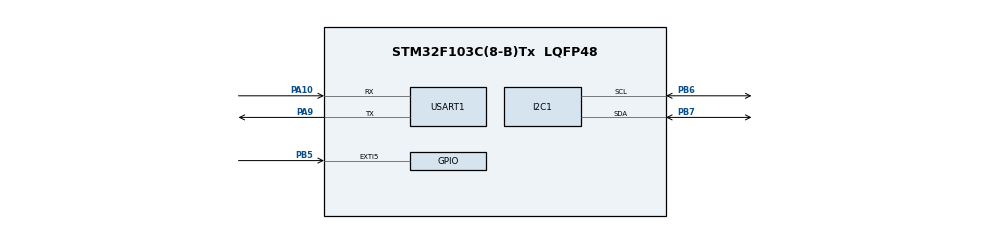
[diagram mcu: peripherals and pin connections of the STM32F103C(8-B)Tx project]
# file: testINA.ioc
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Mcu.Family=STM32F1
Mcu.Name=STM32F103C(8-B)Tx
Mcu.Package=LQFP48
NVIC.EXTI9_5_IRQn=true\:0\:0\:false\:false\:true\:true\:true
NVIC.I2C1_EV_IRQn=true\:0\:0\:false\:false\:true\:true\:true
NVIC.PriorityGroup=NVIC_PRIORITYGROUP_4
NVIC.USART1_IRQn=true\:0\:0\:false\:false\:true\:true\:true
PA10.Mode=Asynchronous
PA10.Signal=USART1_RX
PA13.Mode=Serial_Wire
PA13.Signal=SYS_JTMS-SWDIO
PA14.Mode=Serial_Wire
PA14.Signal=SYS_JTCK-SWCLK
PA9.Mode=Asynchronous
PA9.Signal=USART1_TX
PB5.GPIO_ModeDefaultEXTI=GPIO_MODE_IT_FALLING
PB5.Signal=GPXTI5
PB6.Mode=I2C
PB6.Signal=I2C1_SCL
PB7.Mode=I2C
PB7.Signal=I2C1_SDA
PD0-OSC_IN.Mode=HSE-External-Oscillator
PD0-OSC_IN.Signal=RCC_OSC_IN
PD1-OSC_OUT.Mode=HSE-External-Oscillator
PD1-OSC_OUT.Signal=RCC_OSC_OUT
ProjectManager.HeapSize=0x200
ProjectManager.StackSize=0x400
ProjectManager.TargetToolchain=MDK-ARM V5
RCC.APB1Freq_Value=8000000
RCC.APB2Freq_Value=8000000
RCC.SYSCLKSource=RCC_SYSCLKSOURCE_HSE
USART1.VirtualMode=VM_ASYNC
board=custom

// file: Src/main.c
/* USER CODE BEGIN Header */
/**
  ******************************************************************************
  * @file           : main.c
  * @brief          : Main program body
  ******************************************************************************
  * @attention
  *
  * <h2><center>&copy; Copyright (c) 2020 STMicroelectronics.
  * All rights reserved.</center></h2>
  *
  * This software component is licensed by ST under BSD 3-Clause license,
  * the "License"; You may not use this file except in compliance with the
  * License. You may obtain a copy of the License at:
  *                        opensource.org/licenses/BSD-3-Clause
  *
  ******************************************************************************
  */
/* USER CODE END Header */

#include "main.h"

/* USER CODE BEGIN Includes */
#include "INA288.h"
/* USER CODE END Includes */

I2C_HandleTypeDef hi2c1;

UART_HandleTypeDef huart1;

void SystemClock_Config(void);
static void MX_GPIO_Init(void);
static void MX_I2C1_Init(void);
static void MX_USART1_UART_Init(void);
/* USER CODE BEGIN PFP */
float current, voltage, power,x;
uint32_t cur,vol;
uint16_t test,x1,x2;
uint8_t d[3]={REG_ADCCONFIG_2,0x18,0x24};
/* USER CODE END PFP */

int main(void)
{

  /* MCU Configuration--------------------------------------------------------*/

  /* Reset of all peripherals, Initializes the Flash interface and the Systick. */
  HAL_Init();

  /* Configure the system clock */
  SystemClock_Config();

  /* Initialize all configured peripherals */
  MX_GPIO_Init();
  MX_I2C1_Init();
  MX_USART1_UART_Init();
  /* USER CODE BEGIN 2 */
//HAL_I2C_Mem_Write(&hi2c1,INA288_address,REG_ADCCONFIG_2,I2C_MEMADD_SIZE_8BIT,d,2,100);
//HAL_I2C_Master_Transmit(&hi2c1,(INA288_address<<1),d,3,100);
//INA288_write_16(REG_ADCCONFIG_2,INA288_ADCCONFIG_2);
INA288_init();
  /* USER CODE END 2 */

  /* Infinite loop */
  /* USER CODE BEGIN WHILE */
  while (1)
  {

		//x1=INA288_read_16(REG_CONFIG_1);
		test=INA288_read_16(REG_CURRLSBCALC_3);
		x=INA288_read_16(REG_DIAG_ALRT)&0x02;
    if(x)
    {
      cur=INA288_read_24(REG_CURRENT);
      //UART_Trans_24(cur);
      current=cur*CURRENT_LSB0;
      vol=INA288_read_24(REG_VBUS);
      //UART_Trans_24(vol);
      voltage=vol*INA288_VBus;
    }
    /* USER CODE END WHILE */

  }
}

void SystemClock_Config(void)
{
  RCC_OscInitTypeDef RCC_OscInitStruct = {0};
  RCC_ClkInitTypeDef RCC_ClkInitStruct = {0};

  /** Initializes the CPU, AHB and APB busses clocks
  */
  RCC_OscInitStruct.OscillatorType = RCC_OSCILLATORTYPE_HSE;
  RCC_OscInitStruct.HSEState = RCC_HSE_ON;
  RCC_OscInitStruct.PLL.PLLState = RCC_PLL_NONE;
  if (HAL_RCC_OscConfig(&RCC_OscInitStruct) != HAL_OK)
  {
    Error_Handler();
  }
  /** Initializes the CPU, AHB and APB busses clocks
  */
  RCC_ClkInitStruct.ClockType = RCC_CLOCKTYPE_HCLK|RCC_CLOCKTYPE_SYSCLK
                              |RCC_CLOCKTYPE_PCLK1|RCC_CLOCKTYPE_PCLK2;
  RCC_ClkInitStruct.SYSCLKSource = RCC_SYSCLKSOURCE_HSE;
  RCC_ClkInitStruct.AHBCLKDivider = RCC_SYSCLK_DIV1;
  RCC_ClkInitStruct.APB1CLKDivider = RCC_HCLK_DIV1;
  RCC_ClkInitStruct.APB2CLKDivider = RCC_HCLK_DIV1;

  if (HAL_RCC_ClockConfig(&RCC_ClkInitStruct, FLASH_LATENCY_0) != HAL_OK)
  {
    Error_Handler();
  }
}

static void MX_I2C1_Init(void)
{

  hi2c1.Instance = I2C1;
  hi2c1.Init.ClockSpeed = 100000;
  hi2c1.Init.DutyCycle = I2C_DUTYCYCLE_2;
  hi2c1.Init.OwnAddress1 = 0;
  hi2c1.Init.AddressingMode = I2C_ADDRESSINGMODE_7BIT;
  hi2c1.Init.DualAddressMode = I2C_DUALADDRESS_DISABLE;
  hi2c1.Init.OwnAddress2 = 0;
  hi2c1.Init.GeneralCallMode = I2C_GENERALCALL_DISABLE;
  hi2c1.Init.NoStretchMode = I2C_NOSTRETCH_DISABLE;
  if (HAL_I2C_Init(&hi2c1) != HAL_OK)
  {
    Error_Handler();
  }

}

static void MX_USART1_UART_Init(void)
{

  huart1.Instance = USART1;
  huart1.Init.BaudRate = 115200;
  huart1.Init.WordLength = UART_WORDLENGTH_8B;
  huart1.Init.StopBits = UART_STOPBITS_1;
  huart1.Init.Parity = UART_PARITY_NONE;
  huart1.Init.Mode = UART_MODE_TX_RX;
  huart1.Init.HwFlowCtl = UART_HWCONTROL_NONE;
  huart1.Init.OverSampling = UART_OVERSAMPLING_16;
  if (HAL_UART_Init(&huart1) != HAL_OK)
  {
    Error_Handler();
  }

}

static void MX_GPIO_Init(void)
{
  GPIO_InitTypeDef GPIO_InitStruct = {0};

  /* GPIO Ports Clock Enable */
  __HAL_RCC_GPIOD_CLK_ENABLE();
  __HAL_RCC_GPIOA_CLK_ENABLE();
  __HAL_RCC_GPIOB_CLK_ENABLE();

  /*Configure GPIO pin : PB5 */
  GPIO_InitStruct.Pin = GPIO_PIN_5;
  GPIO_InitStruct.Mode = GPIO_MODE_IT_FALLING;
  GPIO_InitStruct.Pull = GPIO_NOPULL;
  HAL_GPIO_Init(GPIOB, &GPIO_InitStruct);

  /* EXTI interrupt init*/
  HAL_NVIC_SetPriority(EXTI9_5_IRQn, 0, 0);
  HAL_NVIC_EnableIRQ(EXTI9_5_IRQn);

}

void Error_Handler(void)
{
}

/************************ (C) COPYRIGHT STMicroelectronics *****END OF FILE****/
